# STM32F100xE register map
File version: 1.0
Registers are 32-bit, read-write, reset 0x0 unless marked. A register's access mark holds for its fields unless they carry their own. Offsets are from the block's base; [hi:lo] are bit positions; {n}, {i} and the like mark numbered series.

## BKP — Backup Registers
Base 0x40006C00
{0x0+4i} DR{i} (i=1..10)
  [15:0] D — Backup data
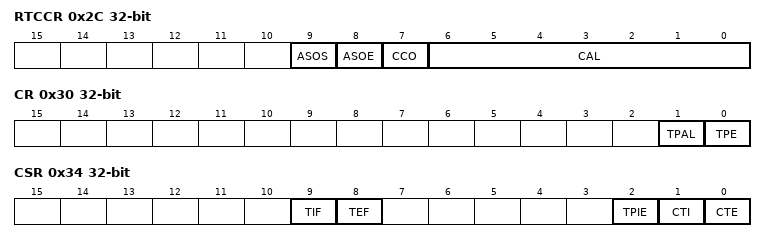
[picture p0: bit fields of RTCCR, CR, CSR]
0x2C RTCCR
  [9] ASOS — Alarm or Second Output Selection
  [8] ASOE — Alarm or Second Output Enable
  [7] CCO — Calibration Clock Output
  [6:0] CAL — Calibration value
0x30 CR
  [1] TPAL — TAMPER pin active level
    1=LOW (A high level on the TAMPER pin resets all data backup registers (if TPE bit is set)); 0=HIGH (A low level on the TAMPER pin resets all data backup registers (if TPE bit is set))
  [0] TPE — TAMPER pin enable
0x34 CSR
  [9] TIF — Tamper Interrupt Flag
  [8] TEF — Tamper Event Flag
  [2] TPIE — TAMPER Pin interrupt enable
  [1] CTI — Clear Tamper Interrupt
  [0] CTE — Clear Tamper event
{0x14+4i} DR{i} (i=11..42)
  [15:0] D — Backup data

## PWR — Power Control
Base 0x40007000
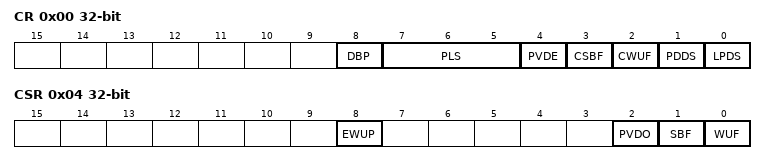
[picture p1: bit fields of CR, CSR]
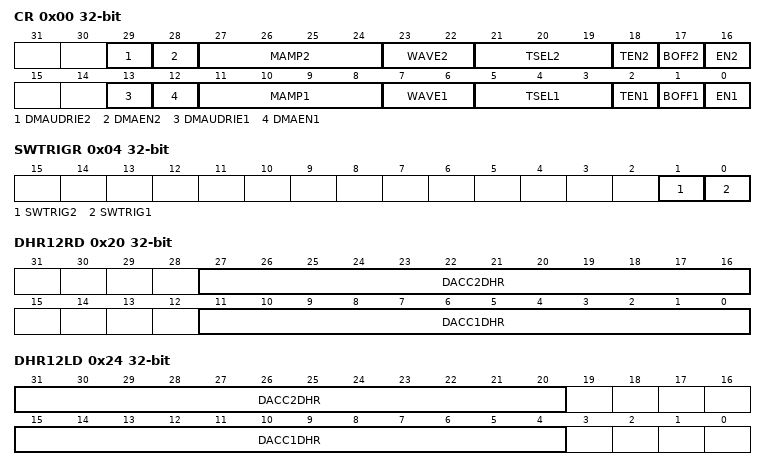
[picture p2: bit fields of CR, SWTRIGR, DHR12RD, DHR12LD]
0x00 CR
  [8] DBP — Disable Backup Domain write protection
  [7:5] PLS — PLS[2:0] bits (PVD Level Selection)
    0=PVDLEVEL_0 (Voltage threshold detected by PVD 2.2 V); 1=PVDLEVEL_1 (Voltage threshold detected by PVD 2.3 V); 2=PVDLEVEL_2 (Voltage threshold detected by PVD 2.4 V); 3=PVDLEVEL_3 (Voltage threshold detected by PVD 2.5 V); 4=PVDLEVEL_4 (Voltage threshold detected by PVD 2.6 V); 5=PVDLEVEL_5 (Voltage threshold detected by PVD 2.7 V); 6=PVDLEVEL_6 (Voltage threshold detected by PVD 2.8 V); 7=PVDLEVEL_7 (Voltage threshold detected by PVD 2.9 V)
  [4] PVDE — Power Voltage Detector Enable
  [3] CSBF — Clear Standby Flag
  [2] CWUF — Clear Wakeup Flag
  [1] PDDS — Power Down Deepsleep
  [0] LPDS — Low-Power Deepsleep
    0=MAIN (Voltage Regulator in main mode during deepsleep mode); 1=LOW_POWER (Voltage Regulator in low-power mode during deepsleep mode)
0x04 CSR
  [8] EWUP — Enable WKUP pin
  [2] PVDO — PVD Output
  [1] SBF — Standby Flag
  [0] WUF — Wakeup Flag

## DAC — Digital to Analog Converter
Base 0x40007400
Same registers: DAC1 0x40007400 (alternate view of DAC)
0x00 CR
  [29] DMAUDRIE2 — DAC channel2 DMA underrun interrupt enable
  [28] DMAEN2 — DAC channel2 DMA enabled
  [27:24] MAMP2 — MAMP2[3:0] (DAC channel2 Mask/Amplitude selector)
  [23:22] WAVE2 — WAVE2[1:0] (DAC channel2 noise/triangle wave generation enable)
  [21:19] TSEL2 — TSEL2[2:0] (DAC channel2 Trigger selection)
  [18] TEN2 — DAC channel2 Trigger enable
  [17] BOFF2 — DAC channel2 output buffer disable
  [16] EN2 — DAC channel2 enable
  [13] DMAUDRIE1 — DAC channel1 DMA underrun interrupt enable
  [12] DMAEN1 — DAC channel1 DMA enable
  [11:8] MAMP1 — MAMP1[3:0] (DAC channel1 Mask/Amplitude selector)
  [7:6] WAVE1 — WAVE1[1:0] (DAC channel1 noise/triangle wave generation enable)
  [5:3] TSEL1 — TSEL1[2:0] (DAC channel1 Trigger selection)
  [2] TEN1 — DAC channel1 Trigger enable
  [1] BOFF1 — DAC channel1 output buffer disable
  [0] EN1 — DAC channel1 enable
0x04 SWTRIGR
  [1] SWTRIG2 — DAC channel2 software trigger
  [0] SWTRIG1 — DAC channel1 software trigger
0x08 DHR12R1
  [11:0] DACC1DHR — DAC channel1 12-bit Right aligned data
0x0C DHR12L1
  [15:4] DACC1DHR — DAC channel1 12-bit Left aligned data
0x10 DHR8R1
  [7:0] DACC1DHR — DAC channel1 8-bit Right aligned data
0x14 DHR12R2
  [11:0] DACC2DHR — DAC channel2 12-bit Right aligned data
0x18 DHR12L2
  [15:4] DACC2DHR — DAC channel2 12-bit Left aligned data
0x1C DHR8R2
  [7:0] DACC2DHR — DAC channel2 8-bit Right aligned data
0x20 DHR12RD
  [27:16] DACC2DHR — DAC channel2 12-bit Right aligned data
  [11:0] DACC1DHR — DAC channel1 12-bit Right aligned data
0x24 DHR12LD
  [31:20] DACC2DHR — DAC channel2 12-bit Left aligned data
  [15:4] DACC1DHR — DAC channel1 12-bit Left aligned data
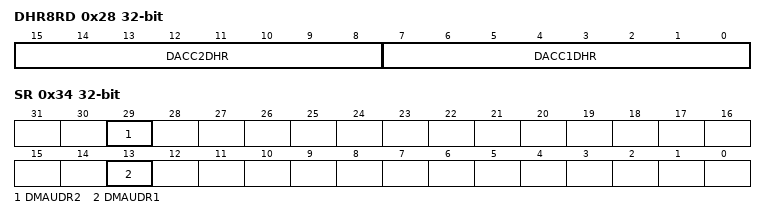
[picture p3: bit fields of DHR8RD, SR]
0x28 DHR8RD
  [15:8] DACC2DHR — DAC channel2 8-bit Right aligned data
  [7:0] DACC1DHR — DAC channel1 8-bit Right aligned data
0x2C DOR1
  [11:0] DACC1DOR — DAC channel1 data output
0x30 DOR2
  [11:0] DACC2DOR — DAC channel2 data output
0x34 SR
  [29] DMAUDR2 — DAC channel2 DMA underrun flag
  [13] DMAUDR1 — DAC channel1 DMA underrun flag
